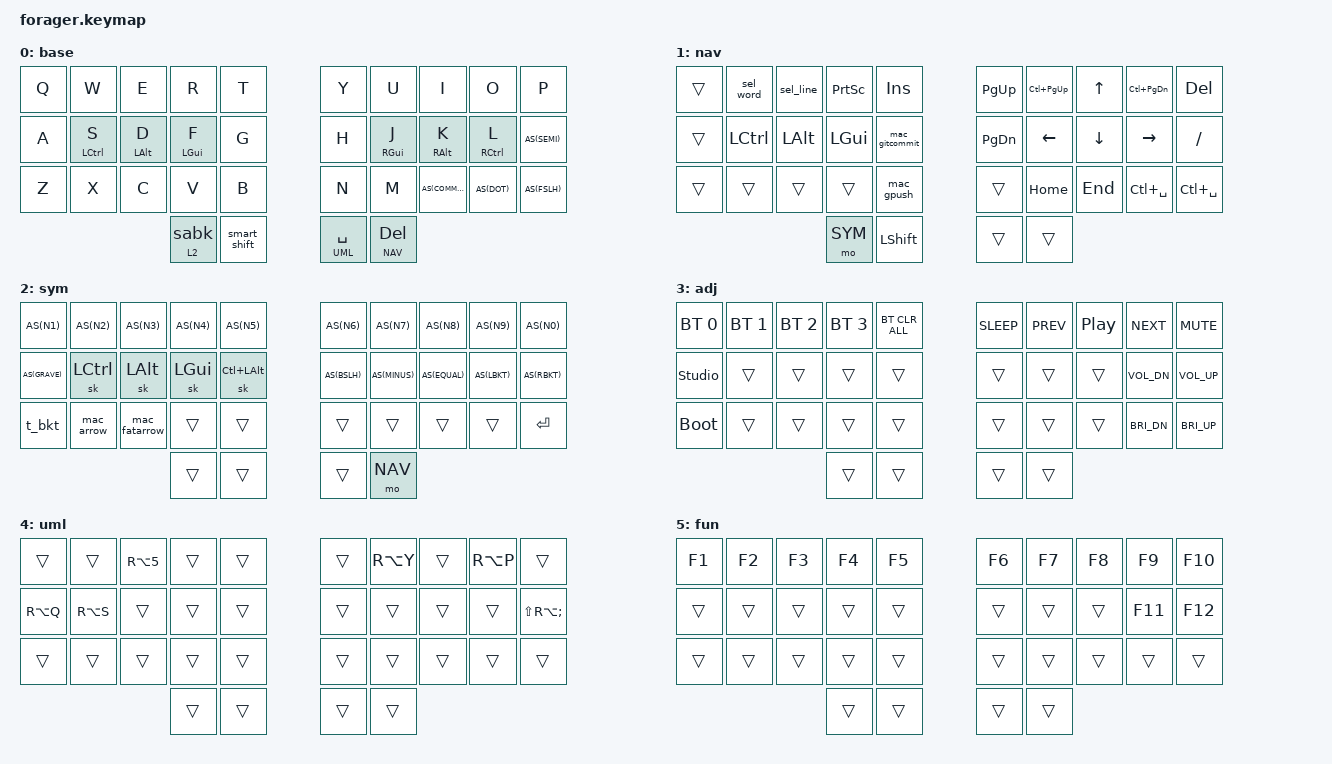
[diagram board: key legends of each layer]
#include <behaviors.dtsi>
#include <dt-bindings/zmk/keys.h>
#include <dt-bindings/zmk/bt.h>
#include <dt-bindings/zmk/outputs.h>

#define BASE 0
#define NAV  1
#define SYM  2
#define ADJ  3
#define UML  4
#define FUN  5

#define AS(keycode) &as LS(keycode) keycode     // Autoshift Macro
#define MEH LS(LC(LALT))

/ {
    behaviors {
        as: auto_shift {
            compatible = "zmk,behavior-hold-tap";
            #binding-cells = <2>;
            tapping-term-ms = <250>;
            require-prior-idle-ms = <100>;
            flavor = "tap-preferred";
            bindings = <&kp>, <&kp>;
        };
        ht: hold_tap {
            compatible = "zmk,behavior-hold-tap";
            #binding-cells = <2>;
            tapping-term-ms = <200>;
            flavor = "balanced";
            bindings = <&kp>, <&kp>;
        };
        sabk: shift_to_alt_backspace {
            compatible = "zmk,behavior-mod-morph";
            #binding-cells = <0>;
            bindings = <&kp BSPC>, <&kp LA(BSPC)>;
            mods = <(MOD_LSFT|MOD_RSFT)>;
        };
        smart_shift: smart_shift {
            compatible = "zmk,behavior-mod-morph";
            #binding-cells = <0>;
            bindings = <&sk LSHFT>, <&caps_word>;
            mods = <(MOD_LSFT|MOD_RSFT)>;
        };
        sym_bspc: left_thumb_hold_tap {
            compatible = "zmk,behavior-hold-tap";
            #binding-cells = <2>;
            flavor = "tap-preferred";
            tapping-term-ms = <150>;
            quick-tap-ms = <200>;
            bindings = <&mo>, <&sabk>;
        };
        lhm: left_homerow_mods {
            compatible = "zmk,behavior-hold-tap";
            #binding-cells = <2>;
            flavor = "balanced";
            tapping-term-ms = <280>;
            quick-tap-ms = <175>;
            require-prior-idle-ms = <150>;
            bindings = <&kp>, <&kp>;
            hold-trigger-key-positions = <5 6 7 8 9 15 16 17 18 19 25 26 27 28 29 30 31 32 33>;
        };
        rhm: right_homerow_mods {
            compatible = "zmk,behavior-hold-tap";
            #binding-cells = <2>;
            flavor = "balanced";
            tapping-term-ms = <280>;
            quick-tap-ms = <175>;
            require-prior-idle-ms = <150>;
            bindings = <&kp>, <&kp>;
            hold-trigger-key-positions = <0 1 2 3 4 10 11 12 13 14 20 21 22 23 24 30 31 32 33>;
        };
    };

    conditional_layers {
        compatible = "zmk,conditional-layers";
        tri_layer {
            if-layers = <1 2>;
            then-layer = <3>;
        };
        fun_layer {
            if-layers = <2 4>;
            then-layer = <5>;
        };
    };

    keymap {
        compatible = "zmk,keymap";

        base {
            bindings = <
            &kp Q           &kp W           &kp E           &kp R           &kp T                                           &kp Y           &kp U           &kp I           &kp O           &kp P
            &kp A           &lhm LCTRL S    &lhm LALT D     &lhm LGUI F     &kp G                                           &kp H           &rhm RGUI J     &rhm RALT K     &rhm RCTRL L    AS(SEMI)
            &kp Z           &kp X           &kp C           &kp V           &kp B                                           &kp N           &kp M           AS(COMMA)       AS(DOT)         AS(FSLH)
                                                                            &sym_bspc 2 0   &smart_shift   &lt UML SPACE    &lt NAV DELETE
            >;
        };

        nav {
            bindings = <
            &trans          &sel_word       &sel_line       &kp PRINTSCREEN &kp INS                                         &kp PAGE_UP     &kp LC(PG_UP)   &kp UP          &kp LC(PG_DN)   &kp DELETE
            &trans          &kp LCTRL       &kp LALT        &kp LGUI        &mac_gitcommit                                  &kp PAGE_DOWN   &kp LEFT        &kp DOWN        &kp RIGHT       &kp SLASH
            &trans          &trans          &trans          &trans          &mac_gpush                                      &trans          &kp HOME        &kp END         &kp LC(SPACE)   &kp LC(SPACE)
                                                                            &mo SYM         &kp LSHFT       &trans          &trans
            >;
        };

        sym {
            bindings = <
            AS(N1)          AS(N2)          AS(N3)          AS(N4)          AS(N5)                                          AS(N6)          AS(N7)          AS(N8)          AS(N9)          AS(N0)
            AS(GRAVE)       &sk LCTRL       &sk LALT        &sk LGUI        &sk LC(LALT)                                    AS(BSLH)        AS(MINUS)       AS(EQUAL)       AS(LBKT)        AS(RBKT)
            &t_bkt          &mac_arrow      &mac_fatarrow   &trans          &trans                                          &trans          &trans          &trans          &trans          &kp ENTER
                                                                            &trans          &trans          &trans          &mo NAV
            >;
        };

        adj {
            bindings = <
            &bt BT_SEL 0    &bt BT_SEL 1    &bt BT_SEL 2    &bt BT_SEL 3    &bt BT_CLR_ALL                                  &kp C_SLEEP     &kp C_PREV      &kp C_PP        &kp C_NEXT      &kp C_MUTE
            &studio_unlock  &trans          &trans          &trans          &trans                                          &trans          &trans          &trans          &kp C_VOL_DN    &kp C_VOL_UP
            &bootloader     &trans          &trans          &trans          &trans                                          &trans          &trans          &trans          &kp C_BRI_DN    &kp C_BRI_UP
                                                                            &trans          &trans          &trans          &trans
            >;
        };

        uml {
            bindings = <
            &trans          &trans          &kp RA(N5)      &trans          &trans                                          &trans          &kp RA(Y)       &trans          &kp RA(P)       &trans
            &kp RA(Q)       &kp RA(S)       &trans          &trans          &trans                                          &trans          &trans          &trans          &trans          &kp LS(RA(SEMI))
            &trans          &trans          &trans          &trans          &trans                                          &trans          &trans          &trans          &trans          &trans
                                                                            &trans          &trans          &trans          &trans
            >;
        };

        fun {
            bindings = <
            &kp F1          &kp F2          &kp F3          &kp F4          &kp F5                                          &kp F6          &kp F7          &kp F8          &kp F9          &kp F10
            &trans          &trans          &trans          &trans          &trans                                          &trans          &trans          &trans          &kp F11         &kp F12
            &trans          &trans          &trans          &trans          &trans                                          &trans          &trans          &trans          &trans          &trans
                                                                            &trans          &trans          &trans          &trans
            >;
        };
    };
};

&lt {
    // require-prior-idle-ms = <100>;
    tapping-term-ms = <150>;
    quick-tap-ms = <200>;
};

&mt {
    quick-tap-ms = <200>;
};

&sk {
    release-after-ms = <500>;
    quick-release;
};


/ {
    macros {

        // Return-Pfeil (->) für Typisierungen und Funktionsdefinitionen
        mac_arrow: mac_arrow {
            compatible = "zmk,behavior-macro";
            #binding-cells = <0>;
            bindings = <&kp MINUS &kp GT>;
        };

        // Fat Arrow (=>) für Match-Arms
        mac_fatarrow: mac_fatarrow {
            compatible = "zmk,behavior-macro";
            #binding-cells = <0>;
            bindings = <&kp EQUAL &kp GT>;
        };

        mac_gitcommit: mac_gitcommit {
            label = "GIT_COMMIT";
            compatible = "zmk,behavior-macro";
            #binding-cells = <0>;
            wait-ms = <10>;
            tap-ms = <10>;
            bindings = <&kp G &kp I &kp T &kp SPACE &kp C &kp O &kp M &kp M &kp I &kp T &kp SPACE &kp MINUS &kp M &kp SPACE &kp DQT &kp DQT &kp LEFT>;
        };

        t_bkt: triple_backtick {
            label = "TRIPLE_BACKTICK";
            compatible = "zmk,behavior-macro";
            #binding-cells = <0>;
            wait-ms = <10>;
            tap-ms = <10>;
            bindings = <&kp GRAVE &kp GRAVE &kp GRAVE>;
        };

        // Wählt die gesamte aktuelle Zeile aus (Windows/Linux)
        // Logik: Springt zum Anfang der Zeile (HOME) und markiert bis zum Ende (SHIFT + END)
        sel_line: select_line {
            label = "SELECT_LINE";
            compatible = "zmk,behavior-macro";
            #binding-cells = <0>;
            wait-ms = <10>;
            tap-ms = <10>;
            bindings = <&kp HOME>, <&kp LS(END)>;
        };

        // Wählt das aktuelle Wort aus (Windows/Linux)
        // Logik: Springt zum Anfang des nächsten Wortes (CTRL+RIGHT)
        // und markiert zurück zum Anfang des aktuellen Wortes (CTRL+SHIFT+LEFT)
        sel_word: select_word {
            label = "SELECT_WORD";
            compatible = "zmk,behavior-macro";
            #binding-cells = <0>;
            wait-ms = <10>;
            tap-ms = <10>;
            bindings = <&kp LC(RIGHT)>, <&kp LC(LS(LEFT))>;
        };

        qusp: qusp {
            label = "quote space";
            compatible = "zmk,behavior-macro";
            #binding-cells = <0>;
            bindings
                = <&macro_tap &kp DQT>
                , <&macro_tap &kp SPACE>
                ;
        };

        sqsp: sqsp {
            label = "single quote space";
            compatible = "zmk,behavior-macro";
            #binding-cells = <0>;
            bindings
                = <&macro_tap &kp SQT>
                , <&macro_tap &kp SPACE>
                ;
        };

        // 1. Docker Build (Build-Time Versioning)
        // Tippt: docker build --build-arg VERSION=
        mac_docker: mac_docker {
            label = "DOCKER_BUILD";
            compatible = "zmk,behavior-macro";
            #binding-cells = <0>;
            wait-ms = <10>;
            tap-ms = <10>;
            bindings = <&kp D &kp O &kp C &kp K &kp E &kp R &kp SPACE
                        &kp B &kp U &kp I &kp L &kp D &kp SPACE
                        &kp MINUS &kp MINUS &kp B &kp U &kp I &kp L &kp D &kp MINUS &kp A &kp R &kp G &kp SPACE
                        &kp LS(V) &kp LS(E) &kp LS(R) &kp LS(S) &kp LS(I) &kp LS(O) &kp LS(N) &kp EQUAL>;
        };

        // 2. Kubernetes Pods abfragen
        // Tippt: kubectl get pods (und drückt direkt Enter)
        mac_kpods: mac_kpods {
            label = "KUBECTL_PODS";
            compatible = "zmk,behavior-macro";
            #binding-cells = <0>;
            wait-ms = <10>;
            tap-ms = <10>;
            bindings = <&kp K &kp U &kp B &kp E &kp C &kp T &kp L &kp SPACE
                        &kp G &kp E &kp T &kp SPACE
                        &kp P &kp O &kp D &kp S &kp ENTER>;
        };

        // 3. Git Push (Aktuellen Branch pushen)
        // Tippt: git push origin HEAD (und drückt direkt Enter)
        mac_gpush: mac_gpush {
            label = "GIT_PUSH";
            compatible = "zmk,behavior-macro";
            #binding-cells = <0>;
            wait-ms = <10>;
            tap-ms = <10>;
            bindings = <&kp G &kp I &kp T &kp SPACE
                        &kp P &kp U &kp S &kp H &kp SPACE
                        &kp O &kp R &kp I &kp G &kp I &kp N &kp SPACE
                        &kp LS(H) &kp LS(E) &kp LS(A) &kp LS(D) &kp ENTER>;
        };
    };
};

/*                     34 KEY MATRIX

  ╭────────────────────┬────────────────────╮
  │  0   1   2   3   4 │  5   6   7   8   9 │
  │ 10  11  12  13  14 │ 15  16  17  18  19 │
  │ 20  21  22  23  24 │ 25  26  27  28  29 │
  ╰───────────╮ 30  31 │ 32  33 ╭───────────╯
              ╰────────┴────────╯              */

/ {
    combos {
        compatible = "zmk,combos";

        Minus {
            bindings = <&kp MINUS>;
            key-positions = <12 13>;
        };

        Underscore {
            bindings = <&kp UNDERSCORE>;
            key-positions = <16 17>;
        };

        LeftBrace {
            bindings = <&kp LEFT_BRACE>;
            key-positions = <3  4>;
        };

        LeftBracket {
            bindings = <&kp LEFT_BRACKET>;
            key-positions = <13 14>;
        };

        LeftParenthesis {
            bindings = <&kp LEFT_PARENTHESIS>;
            key-positions = <23 24>;
        };

        RightBrace {
            bindings = <&kp RIGHT_BRACE>;
            key-positions = <5 6>;
        };

        RightBracket {
            bindings = <&kp RIGHT_BRACKET>;
            key-positions = <15 16>;
        };

        RightParenthesis {
            bindings = <&kp RIGHT_PARENTHESIS>;
            key-positions = <25 26>;
        };

        DoubleQuotes {
            bindings = <&qusp>;
            key-positions = <22 23>;
        };

        Quote {
            bindings = <&sqsp>;
            key-positions = <26 27>;
        };

        equal {
            bindings = <&kp EQUAL>;
            key-positions = <18 19>;
        };

        enter {
            bindings = <&kp ENTER>;
            key-positions = <28 29>;
        };

        WordBackspace {
            bindings = <&kp LC(BACKSPACE)>;
            key-positions = <8 9>;
        };

        capsword {
            bindings = <&caps_word>;
            key-positions = <13 16>;
        };

        Esc {
            bindings = <&kp ESCAPE>;
            key-positions = <0 1>;
        };

        Tab {
            bindings = <&kp TAB>;
            key-positions = <10 11>;
        };


    };
};
